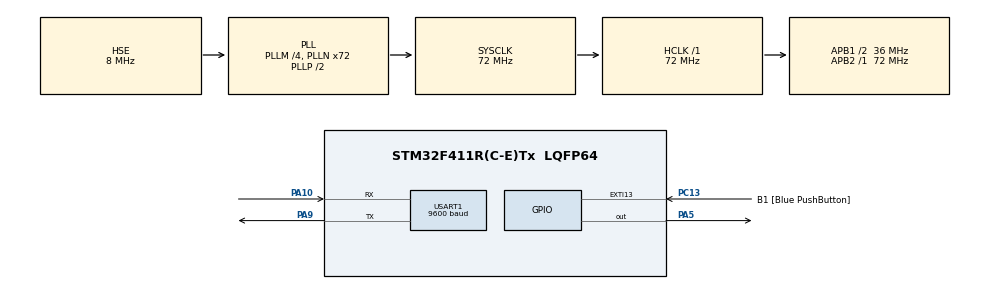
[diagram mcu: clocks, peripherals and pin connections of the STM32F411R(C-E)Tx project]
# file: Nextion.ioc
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Mcu.Family=STM32F4
RCC.PLLSourceVirtual=RCC_PLLSOURCE_HSE
RCC.CortexFreq_Value=72000000
PA10.Mode=Asynchronous
PC13-ANTI_TAMP.GPIO_Label=B1 [Blue PushButton]
USART1.BaudRate=9600
PA14.GPIO_Label=TCK
PH1\ -\ OSC_OUT.Mode=HSE-External-Oscillator
RCC.APB1CLKDivider=RCC_HCLK_DIV2
PC14-OSC32_IN.Signal=RCC_OSC32_IN
RCC.SYSCLKSource=RCC_SYSCLKSOURCE_PLLCLK
ProjectManager.StackSize=0x400
PA13.Signal=SYS_JTMS-SWDIO
PA9.Mode=Asynchronous
PH0\ -\ OSC_IN.Mode=HSE-External-Oscillator
PH0\ -\ OSC_IN.Signal=RCC_OSC_IN
ProjectManager.TargetToolchain=STM32CubeIDE
RCC.HCLKFreq_Value=72000000
RCC.APB2TimFreq_Value=72000000
PA9.Signal=USART1_TX
RCC.LSE_VALUE=32768
PC15-OSC32_OUT.Signal=RCC_OSC32_OUT
RCC.AHBFreq_Value=72000000
PA5.Signal=GPIO_Output
RCC.HSE_VALUE=8000000
PH1\ -\ OSC_OUT.Signal=RCC_OSC_OUT
board=NUCLEO-F411RE
PC13-ANTI_TAMP.Signal=GPXTI13
RCC.VCOOutputFreq_Value=144000000
RCC.APB2Freq_Value=72000000
Mcu.Name=STM32F411R(C-E)Tx
PA2.Signal=USART2_TX
PA13.GPIO_Label=TMS
RCC.FLatency-AdvancedSettings=FLASH_LATENCY_2
RCC.48MHZClocksFreq_Value=36000000
PB3.Signal=SYS_JTDO-SWO
RCC.SYSCLKFreq_VALUE=72000000
Mcu.Package=LQFP64
USART1.VirtualMode=VM_ASYNC
PC13-ANTI_TAMP.GPIO_ModeDefaultEXTI=GPIO_MODE_IT_FALLING
PA2.GPIO_Label=USART_TX
PA10.Signal=USART1_RX
PA14.Signal=SYS_JTCK-SWCLK
ProjectManager.HeapSize=0x200
RCC.HSI_VALUE=16000000
NVIC.PriorityGroup=NVIC_PRIORITYGROUP_0
RCC.PLLM=4
RCC.PLLN=72
RCC.APB1TimFreq_Value=72000000
NVIC.USART1_IRQn=true\:0\:0\:false\:false\:true\:true\:true
RCC.APB1Freq_Value=36000000
PA3.GPIO_Label=USART_RX
PA3.Signal=USART2_RX
PB3.GPIO_Label=SWO

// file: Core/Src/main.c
/* USER CODE BEGIN Header */
/**
  ******************************************************************************
  * @file           : main.c
  * @brief          : Main program body
  ******************************************************************************
  * @attention
  *
  * <h2><center>&copy; Copyright (c) 2021 STMicroelectronics.
  * All rights reserved.</center></h2>
  *
  * This software component is licensed by ST under BSD 3-Clause license,
  * the "License"; You may not use this file except in compliance with the
  * License. You may obtain a copy of the License at:
  *                        opensource.org/licenses/BSD-3-Clause
  *
  ******************************************************************************
  */
/* USER CODE END Header */
#include "main.h"

UART_HandleTypeDef huart1;

void SystemClock_Config(void);
static void MX_GPIO_Init(void);
static void MX_USART1_UART_Init(void);

/* USER CODE BEGIN 0 */
uint8_t rx_data[5];

/* USER CODE END 0 */

int main(void)
{

  /* MCU Configuration--------------------------------------------------------*/

  /* Reset of all peripherals, Initializes the Flash interface and the Systick. */
  HAL_Init();

  /* Configure the system clock */
  SystemClock_Config();

  /* Initialize all configured peripherals */
  MX_GPIO_Init();
  MX_USART1_UART_Init();

  /* Infinite loop */
  while (1)
  {
	  HAL_UART_Receive(&huart1, rx_data, 5 , 1000);

	  if (rx_data[1] > 0x7f) HAL_GPIO_WritePin(GPIOA, GPIO_PIN_5, GPIO_PIN_SET);
	  else HAL_GPIO_WritePin(GPIOA, GPIO_PIN_5, GPIO_PIN_RESET);

  }
}

void SystemClock_Config(void)
{
  RCC_OscInitTypeDef RCC_OscInitStruct = {0};
  RCC_ClkInitTypeDef RCC_ClkInitStruct = {0};

  /** Configure the main internal regulator output voltage
  */
  __HAL_RCC_PWR_CLK_ENABLE();
  __HAL_PWR_VOLTAGESCALING_CONFIG(PWR_REGULATOR_VOLTAGE_SCALE1);
  /** Initializes the RCC Oscillators according to the specified parameters
  * in the RCC_OscInitTypeDef structure.
  */
  RCC_OscInitStruct.OscillatorType = RCC_OSCILLATORTYPE_HSE;
  RCC_OscInitStruct.HSEState = RCC_HSE_ON;
  RCC_OscInitStruct.PLL.PLLState = RCC_PLL_ON;
  RCC_OscInitStruct.PLL.PLLSource = RCC_PLLSOURCE_HSE;
  RCC_OscInitStruct.PLL.PLLM = 4;
  RCC_OscInitStruct.PLL.PLLN = 72;
  RCC_OscInitStruct.PLL.PLLP = RCC_PLLP_DIV2;
  RCC_OscInitStruct.PLL.PLLQ = 4;
  if (HAL_RCC_OscConfig(&RCC_OscInitStruct) != HAL_OK)
  {
    Error_Handler();
  }
  /** Initializes the CPU, AHB and APB buses clocks
  */
  RCC_ClkInitStruct.ClockType = RCC_CLOCKTYPE_HCLK|RCC_CLOCKTYPE_SYSCLK
                              |RCC_CLOCKTYPE_PCLK1|RCC_CLOCKTYPE_PCLK2;
  RCC_ClkInitStruct.SYSCLKSource = RCC_SYSCLKSOURCE_PLLCLK;
  RCC_ClkInitStruct.AHBCLKDivider = RCC_SYSCLK_DIV1;
  RCC_ClkInitStruct.APB1CLKDivider = RCC_HCLK_DIV2;
  RCC_ClkInitStruct.APB2CLKDivider = RCC_HCLK_DIV1;

  if (HAL_RCC_ClockConfig(&RCC_ClkInitStruct, FLASH_LATENCY_2) != HAL_OK)
  {
    Error_Handler();
  }
}

static void MX_USART1_UART_Init(void)
{

  huart1.Instance = USART1;
  huart1.Init.BaudRate = 9600;
  huart1.Init.WordLength = UART_WORDLENGTH_8B;
  huart1.Init.StopBits = UART_STOPBITS_1;
  huart1.Init.Parity = UART_PARITY_NONE;
  huart1.Init.Mode = UART_MODE_TX_RX;
  huart1.Init.HwFlowCtl = UART_HWCONTROL_NONE;
  huart1.Init.OverSampling = UART_OVERSAMPLING_16;
  if (HAL_UART_Init(&huart1) != HAL_OK)
  {
    Error_Handler();
  }

}

static void MX_GPIO_Init(void)
{
  GPIO_InitTypeDef GPIO_InitStruct = {0};

  /* GPIO Ports Clock Enable */
  __HAL_RCC_GPIOC_CLK_ENABLE();
  __HAL_RCC_GPIOH_CLK_ENABLE();
  __HAL_RCC_GPIOA_CLK_ENABLE();
  __HAL_RCC_GPIOB_CLK_ENABLE();

  /*Configure GPIO pin Output Level */
  HAL_GPIO_WritePin(GPIOA, GPIO_PIN_5, GPIO_PIN_RESET);

  /*Configure GPIO pin : B1_Pin */
  GPIO_InitStruct.Pin = B1_Pin;
  GPIO_InitStruct.Mode = GPIO_MODE_IT_FALLING;
  GPIO_InitStruct.Pull = GPIO_NOPULL;
  HAL_GPIO_Init(B1_GPIO_Port, &GPIO_InitStruct);

  /*Configure GPIO pins : USART_TX_Pin USART_RX_Pin */
  GPIO_InitStruct.Pin = USART_TX_Pin|USART_RX_Pin;
  GPIO_InitStruct.Mode = GPIO_MODE_AF_PP;
  GPIO_InitStruct.Pull = GPIO_NOPULL;
  GPIO_InitStruct.Speed = GPIO_SPEED_FREQ_VERY_HIGH;
  GPIO_InitStruct.Alternate = GPIO_AF7_USART2;
  HAL_GPIO_Init(GPIOA, &GPIO_InitStruct);

  /*Configure GPIO pin : PA5 */
  GPIO_InitStruct.Pin = GPIO_PIN_5;
  GPIO_InitStruct.Mode = GPIO_MODE_OUTPUT_PP;
  GPIO_InitStruct.Pull = GPIO_NOPULL;
  GPIO_InitStruct.Speed = GPIO_SPEED_FREQ_LOW;
  HAL_GPIO_Init(GPIOA, &GPIO_InitStruct);

}

void Error_Handler(void)
{
  __disable_irq();
  while (1)
  {
  }
}

/************************ (C) COPYRIGHT STMicroelectronics *****END OF FILE****/
